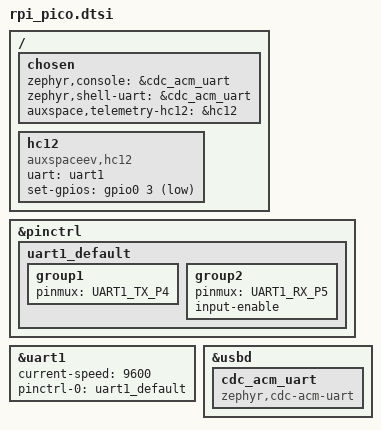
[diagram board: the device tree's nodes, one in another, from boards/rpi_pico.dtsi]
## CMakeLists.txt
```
#-------------------------------------------------------------------------------
# Flight Computer prototype
#
# Copyright (c) 2025-2026 Auxspace e.V.
# SPDX-License-Identifier: Apache-2.0

cmake_minimum_required(VERSION 3.20.0)

# TODO: Exclude zephyr from SCA since it produces false positives
# set(ZEPHYR_SCA_VARIANT gcc)

# Make application-local snippets (e.g. ./snippets/sim) discoverable by
# `west build -S <name>` and twister's SNIPPET= extra_args.
list(APPEND SNIPPET_ROOT ${CMAKE_CURRENT_SOURCE_DIR})

find_package(Zephyr REQUIRED HINTS $ENV{ZEPHYR_BASE})

# For some reason, when using west twister, the app target is not created
# automatically, so we need to create it manually here.
# Building locally and without the zephyr github action, naming this
# "flight_computer" works fine, but as soon as we use west twister inside a
# github-runner context, the target must be named "app":
# > Cannot specify sources for target "app" which is not built by this project.
project(app LANGUAGES C)

target_sources(app PRIVATE
	src/main.c
	src/data.c
	)

target_sources_ifdef(CONFIG_AURORA_FAKE_SENSORS_SYNTH app PRIVATE
	src/fake_sensors.c
	)

if(CONFIG_AURORA_FAKE_SENSORS_REPLAY)
	# Strip surrounding quotes Kconfig keeps on string symbols.
	string(REGEX REPLACE "^\"(.*)\"$" "\\1"
		REPLAY_INPUT_REL "${CONFIG_AURORA_FAKE_SENSORS_REPLAY_INPUT}")
	set(REPLAY_INPUT "${CMAKE_CURRENT_SOURCE_DIR}/../${REPLAY_INPUT_REL}")
	set(REPLAY_GEN  "${CMAKE_CURRENT_SOURCE_DIR}/../tools/gen_flight_replay.py")
	set(REPLAY_OUT  "${CMAKE_CURRENT_BINARY_DIR}/replay_data.c")

	if(NOT EXISTS "${REPLAY_INPUT}")
		message(FATAL_ERROR
			"AURORA_FAKE_SENSORS_REPLAY: input CSV not found: "
			"${REPLAY_INPUT}")
	endif()

	# If a state_audit sits next to flights.csv (default data_logger
	# layout), pass it through so the generator trims to the
	# [BOOST - 4 s, LANDED + 4 s] window.
	get_filename_component(REPLAY_INPUT_DIR "${REPLAY_INPUT}" DIRECTORY)
	set(REPLAY_AUDIT "${REPLAY_INPUT_DIR}/state_audit")
	set(REPLAY_AUDIT_ARGS)
	set(REPLAY_AUDIT_DEPS)
	if(EXISTS "${REPLAY_AUDIT}")
		list(APPEND REPLAY_AUDIT_ARGS --state-audit "${REPLAY_AUDIT}")
		list(APPEND REPLAY_AUDIT_DEPS "${REPLAY_AUDIT}")
    message("-- Found replay audit in flight dir: ${REPLAY_AUDIT}")
	endif()

	add_custom_command(
		OUTPUT  "${REPLAY_OUT}"
		COMMAND ${PYTHON_EXECUTABLE} "${REPLAY_GEN}"
			--input "${REPLAY_INPUT}"
			--output "${REPLAY_OUT}"
			${REPLAY_AUDIT_ARGS}
		DEPENDS "${REPLAY_INPUT}" "${REPLAY_GEN}" ${REPLAY_AUDIT_DEPS}
		COMMENT "Generating replay_data.c from ${REPLAY_INPUT_REL}"
		VERBATIM
	)

	target_sources(app PRIVATE
		src/fake_sensors_replay.c
		"${REPLAY_OUT}"
	)
	target_include_directories(app PRIVATE src)
endif()
```

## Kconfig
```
# Copyright (c) 2025-2026 Auxspace e.V.
# SPDX-License-Identifier: Apache-2.0
#
# This file is the application Kconfig entry point. All application Kconfig
# options can be defined here or included via other application Kconfig files.
# You can browse these options using the west targets menuconfig (terminal) or
# guiconfig (GUI).

menu "Zephyr"

source "Kconfig.zephyr"

endmenu

module = FLIGHT_COMPUTER
module-str = FLIGHT_COMPUTER
source "subsys/logging/Kconfig.template.log_config"

config AURORA_FAKE_SENSORS
	bool "Synthetic IMU/baro data source (no hardware)"
	depends on AURORA_SENSORS
	help
	  Replaces the hardware IMU and barometer polling threads with a
	  synthetic flight-profile generator. The generator publishes
	  imu_data/baro_data messages on the same zbus channels, at the
	  same cadence and thread priorities, so the downstream data path,
	  Kalman filter and state machine can be exercised without real
	  sensors. Works on native_sim and on real hardware targets — use
	  the `sim` snippet (`west build -S sim ...`) to layer this on top
	  of any board. A shell command "sim launch" kicks off the canned
	  ascent/descent profile.

config AURORA_FAKE_SENSORS_REPLAY
	bool "Replay recorded flight log instead of the algorithmic profile"
	depends on IMU && BARO
	select AURORA_FAKE_SENSORS
	help
	  Swap the analytic flight-profile generator (fake_sensors.c) for
	  a playback engine (fake_sensors_replay.c) that streams samples
	  embedded at build time from a recorded flights.csv. Pre-launch
	  the threads hold the rocket stationary by republishing the first
	  recorded sample, so attitude calibration converges as usual; the
	  `sim launch` shell command (or the AURORA_SIM_AUTOTEST autolaunch
	  task) then starts replaying the recording at its original
	  cadence. Implies AURORA_FAKE_SENSORS.

config AURORA_FAKE_SENSORS_SYNTH
	def_bool AURORA_FAKE_SENSORS && !AURORA_FAKE_SENSORS_REPLAY
	help
	  Internal switch: true when AURORA_FAKE_SENSORS is enabled but
	  the replay backend is not, i.e. the algorithmic profile in
	  fake_sensors.c should be compiled in.

config AURORA_FAKE_SENSORS_REPLAY_INPUT
	string "Path to flights.csv used by the replay backend"
	depends on AURORA_FAKE_SENSORS_REPLAY
	default "flight_logs/multimeter/2026-05-03/flight1/flights.csv"
	help
	  Path (relative to the aurora module root, i.e. the directory that
	  contains zephyr/module.yml) to the flights.csv file embedded by
	  the replay generator. May be overridden in prj.conf or via
	  -DCONFIG_AURORA_FAKE_SENSORS_REPLAY_INPUT=... to swap recordings.

config AURORA_SIM_AUTOTEST
	bool "Automated simulation test (CI mode)"
	depends on IMU && BARO
	select AURORA_FAKE_SENSORS
	select ASSERT
	help
	  Enables the full automated flight simulation for CI. Pulls in fake
	  sensors and assertion support, then starts a thread that waits for
	  altitude calibration, and auto-launches the flight
	  profile. Exits with code 0 on SM_LANDED, code 1 on SM_ERROR or after
	  AURORA_SIM_AUTOLAUNCH_TIMEOUT_MS. Run ./zephyr.exe and check the process exit code.

config AURORA_SIM_AUTOLAUNCH_TIMEOUT_MS
	int "Autolaunch watchdog timeout (ms)"
	depends on AURORA_SIM_AUTOTEST
	default 120000
	help
	  Maximum time in milliseconds the autolaunch thread waits for SM_LANDED
	  after triggering the flight profile. Exits with code 1 if this
	  deadline is exceeded.
```

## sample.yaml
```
# Copyright (c) 2026 Auxspace e.V.
# SPDX-License-Identifier: Apache-2.0
#
# This file is provided so that the application can be compiled using Twister,
# the Zephyr testing tool. In this file, multiple combinations can be specified,
# so that you can easily test all of them locally or in CI.
sample:
  description: Flight Computer Application
  name: Flight Computer
common:
  build_only: true
  modules:
    - fatfs
tests:
  app.default:
    platform_allow:
      - sensor_board_v2/rp2350a/hazard3
    integration_platforms:
      - sensor_board_v2/rp2350a/hazard3
  app.native_sim.replay:
    build_only: false
    timeout: 180
    harness: console
    harness_config:
      type: one_line
      regex:
        - "simulation complete"
    extra_overlay_confs:
      - boards/native_sim.conf
    extra_dtc_overlay_files:
      - boards/native_sim.overlay
    extra_configs:
      - CONFIG_AURORA_SIM_AUTOTEST=y
      - CONFIG_AURORA_FAKE_SENSORS_REPLAY=y
    platform_allow:
      - native_sim/native/64
    integration_platforms:
      - native_sim/native/64
  app.default.sysbuild:
    sysbuild: true
    platform_allow:
      - sensor_board_v2/rp2040
      - micrometer@1/esp32s3/procpu
      - micrometer@2/esp32s3/procpu
    integration_platforms:
      - sensor_board_v2/rp2040
      - micrometer@1/esp32s3/procpu
      - micrometer@2/esp32s3/procpu
  app.bench:
    extra_args: SNIPPET="sim;nodisk"
    platform_allow:
      - rpi_pico/rp2040/w
      - rpi_pico2/rp2350a/m33/w
      - sensor_board_v2/rp2040
      - sensor_board_v2/rp2350a/hazard3
    integration_platforms:
      - rpi_pico/rp2040/w
      - rpi_pico2/rp2350a/m33/w
      - sensor_board_v2/rp2040
      - sensor_board_v2/rp2350a/hazard3
  app.debug:
    extra_overlay_confs:
      - debug.conf
    platform_allow:
      - sensor_board_v2/rp2350a/hazard3
    integration_platforms:
      - sensor_board_v2/rp2350a/hazard3
  app.debug.sysbuild:
    sysbuild: true
    extra_overlay_confs:
      - debug.conf
    platform_allow:
      - sensor_board_v2/rp2040
      - micrometer@1/esp32s3/procpu
      - micrometer@2/esp32s3/procpu
    integration_platforms:
      - sensor_board_v2/rp2040
      - micrometer@1/esp32s3/procpu
      - micrometer@2/esp32s3/procpu
```

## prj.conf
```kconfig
# Copyright (c) 2026 Auxspace e.V.
# SPDX-License-Identifier: Apache-2.0
#
# common options, which apply to all boards (will be duplicated in board configs)

# Console and Shell
CONFIG_SHELL=y
CONFIG_SENSOR_SHELL=y

# Boot banner
CONFIG_BOOT_BANNER_STRING="Booting AURORA"

# Logging
CONFIG_LOG=y
CONFIG_LOG_FLUSH_SLEEP_US=1000
CONFIG_LOG_DEFAULT_LEVEL=3
CONFIG_LOG_TIMESTAMP_USE_REALTIME=y
CONFIG_LOG_SPEED=y
CONFIG_LOG_THREAD_ID_PREFIX=y
CONFIG_LOG_INFO_COLOR_GREEN=y
CONFIG_LOG_DBG_COLOR_BLUE=y
CONFIG_LOG_OUTPUT_FORMAT_TIME_TIMESTAMP=y
# CONFIG_LOG_BACKEND_FS_APPEND_TO_NEWEST_FILE is not set
# CONFIG_LOG_MEM_UTILIZATION is not set
CONFIG_LOG_CMDS=y
CONFIG_LOG_RATELIMIT_INTERVAL_MS=500

# State machine
CONFIG_AURORA_STATE_MACHINE=y
CONFIG_AURORA_STATE_MACHINE_SHELL=y

CONFIG_ZBUS=y
CONFIG_ZBUS_CHANNEL_NAME=y
CONFIG_ZBUS_MSG_SUBSCRIBER=y
# Headroom so a transient SD write stall doesn't exhaust the pool and drop
# sensor publishes.
CONFIG_ZBUS_MSG_SUBSCRIBER_NET_BUF_POOL_SIZE=64

# Runtime healthchecks and supervision
CONFIG_STACK_SENTINEL=y
CONFIG_ASSERT=y
```

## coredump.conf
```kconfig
# Copyright (c) 2026 Auxspace e.V.
# SPDX-License-Identifier: Apache-2.0
#
# Post-mortem core dump persisted to the on-board "coredump" flash
# partition, then read back over the shell after the board comes up again:
#
#   uart:~$ coredump find     # is a dump stored, and is it valid?
#   uart:~$ coredump print    # emit the "#CD:" hex stream
#   uart:~$ coredump erase    # invalidate it before the next run
#
# Decode off-target against the matching ELF:
#   zephyr/scripts/coredump/coredump_serial_log_parse.py <captured> out.bin
#   zephyr/scripts/coredump/coredump_gdbserver.py build/zephyr/zephyr.elf out.bin
#
# Stack with the debug overlay for symbols + a text backtrace:
#   west build -b micrometer/esp32s3/procpu@2 aurora/flight_computer \
#       -- -DEXTRA_CONF_FILE="debug.conf;coredump.conf"
#
# Why flash and not BACKEND_LOGGING: on micrometer@2 the console is the
# ESP32-S3 USB-Serial-JTAG, whose poll_out (serial_esp32_usb.c) silently
# DISCARDS characters once the 64-byte TX FIFO stays full for 50 ms. A
# coredump is the largest burst the firmware ever emits and it is written
# in panic mode, so streaming it over that console loses most of it with no
# "dropped" marker. Flash survives the fault, the reboot, and a power
# cycle; the shell read-back afterwards is interrupt-driven and properly
# back-pressured, so it does not drop.

CONFIG_DEBUG_COREDUMP=y
CONFIG_DEBUG_COREDUMP_BACKEND_FLASH_PARTITION=y

# Read the stored dump back out on the next boot.
CONFIG_DEBUG_COREDUMP_SHELL=y

# Registers + the faulting thread's stack only: enough to reconstruct the
# backtrace of a NULL-deref crash. Switch to
# CONFIG_DEBUG_COREDUMP_MEMORY_DUMP_THREADS=y if you need every thread's
# stack -- but see the size budget below first, it will not fit.
CONFIG_DEBUG_COREDUMP_MEMORY_DUMP_MIN=y

# Size budget. The coredump partition inherited from
# espressif/partitions_0x0_amp_4M.dtsi is 4 KiB at 0x3ff000; the backend's
# 16-byte header (write-block-size is 4, so no erase-block padding) leaves
# 4080 bytes for data. The stack-top limits default to -1 == "dump to the
# end of the stack region", which for a 4 KiB thread stack overruns the
# partition and truncates the dump. Bound them so the whole thing fits:
#
#   coredump hdr ~12 + Xtensa arch block ~200 + k_thread ~350
#   + block headers ~30 + 2048 stack  ==  ~2.6 KiB of 4080.
#
# 2 KiB of stack top is generous on Xtensa, where register-window spills
# make frames large.
CONFIG_DEBUG_COREDUMP_THREAD_STACK_TOP=y
CONFIG_DEBUG_COREDUMP_THREAD_STACK_TOP_LIMIT_FOR_CURRENT=2048
CONFIG_DEBUG_COREDUMP_THREAD_STACK_TOP_LIMIT=1024

# Take the SD card off the panic path. The FS log backend flushes
# synchronously during a panic; a real crash then looks like a freeze.
# Console/UART still gets everything. Disabling it here also doubles as the
# test for whether the SD/FATFS is itself the freeze source.
# if the freezes stop with this off, the card/filesystem is the culprit.
CONFIG_LOG_BACKEND_FS=n
```

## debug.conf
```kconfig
# Copyright (c) 2021 Nordic Semiconductor ASA
# Copyright (c) 2026 Auxspace e.V.
# SPDX-License-Identifier: Apache-2.0
#
# This is a Kconfig fragment which can be used to enable debug-related options
# in the application. See the README for more details.

# kernel
CONFIG_DEBUG=y
CONFIG_DEBUG_THREAD_INFO=y

# Fatal-error handling.
#
# Zephyr's default with RESET_ON_FATAL_ERROR=n is arch_system_halt(): the
# board stops dead where it faulted. On micrometer@2 that is
# indistinguishable from a brownout or a flat pack, because the halt takes
# the console with it and the panic banner is lost in the USB-Serial-JTAG
# FIFO (see coredump.conf). Rebooting instead means the board comes back,
# re-prints the boot banner -- which is itself the proof that this was a
# fault and not a power loss -- and can be asked for the stored coredump.
#
# Debug-only on purpose: a flight build should not silently reboot a live
# state machine, so this stays out of prj.conf.
CONFIG_RESET_ON_FATAL_ERROR=y

# Reset-cause reporting. hwinfo_esp32 distinguishes POR / PIN / SOFTWARE /
# WATCHDOG / CPU_LOCKUP / BROWNOUT / LOW_POWER_WAKE, which is the one thing
# the console genuinely cannot tell you: whether the board panicked, was
# reset by the watchdog, browned out, or just lost power. main() logs and
# clears it at boot.
CONFIG_HWINFO=y

# Stack-overflow sanitisers
CONFIG_HW_STACK_PROTECTION=y
CONFIG_INIT_STACKS=y
CONFIG_THREAD_STACK_INFO=y
CONFIG_STACK_USAGE=y
CONFIG_EXCEPTION_STACK_TRACE=y

# compiler
CONFIG_SYMTAB=y
CONFIG_SYMTAB_SHELL=y
CONFIG_DEBUG_OPTIMIZATIONS=y
# Keep file:line (that is what names a panic) but drop the condition
# expression, which is the long half of every assert string. Assert strings
# land in DRAM rodata on esp32s3, and DRAM is the binding constraint here.
CONFIG_ASSERT_NO_COND_INFO=y

# Paying for CONFIG_ASSERT: its strings cost ~20 KB of DRAM, which does not
# fit on micrometer@2 at the production buffer sizes. Buy it back from the
# post-flight conversion staging buffers -- they only set how often
# data_logger_convert() calls fs_write(), so the cost is more/smaller SD
# writes after landing and nothing at flight time.
#
# These belong here rather than in the board .conf: EXTRA_CONF_FILE is merged
# after the board fragment, so they override it for debug builds only and the
# production image keeps the full 16 KiB buffers.
CONFIG_DATA_LOGGER_CSV_BUF_SIZE=8192

# thread analyzing
CONFIG_THREAD_ANALYZER=y
CONFIG_THREAD_ANALYZER_AUTO=y
CONFIG_THREAD_ANALYZER_AUTO_STACK_SIZE=2048
CONFIG_THREAD_ANALYZER_USE_LOG=y

# logging
CONFIG_LOG=y

CONFIG_FS_LOG_LEVEL_DBG=y
CONFIG_PYRO_LOG_LEVEL_DBG=y
CONFIG_AURORA_SENSORS_LOG_LEVEL_DBG=y
CONFIG_AURORA_FILTER_LOG_LEVEL_DBG=y
CONFIG_DATA_LOGGER_LOG_LEVEL_DBG=y
CONFIG_STATE_MACHINE_LOG_LEVEL_DBG=y
CONFIG_AURORA_NOTIFY_LOG_LEVEL_DBG=y
CONFIG_AURORA_PWM_MELODY_LOG_LEVEL_DBG=y
CONFIG_AURORA_POWERFAIL_LOG_LEVEL_DBG=y
CONFIG_FLIGHT_COMPUTER_LOG_LEVEL_DBG=y
CONFIG_AURORA_TELEMETRY_LOG_LEVEL_DBG=y
CONFIG_AURORA_PAD_LINK_LOG_LEVEL_DBG=y
CONFIG_AURORA_WATCHDOG_LOG_LEVEL_DBG=y

# powerfail
CONFIG_AURORA_POWERFAIL_SHUTDOWN=n

# Extra Shells for Debugging
CONFIG_ADC_SHELL=y
CONFIG_AURORA_STATE_MACHINE_SHELL=y
CONFIG_CAN_SHELL=y
CONFIG_GPIO_SHELL=y
CONFIG_PWM_SHELL=y
CONFIG_PYRO_SHELL=y
CONFIG_WDT_SHELL=y
```

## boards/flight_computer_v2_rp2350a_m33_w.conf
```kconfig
CONFIG_USE_DT_CODE_PARTITION=y
CONFIG_MAIN_STACK_SIZE=2048
CONFIG_CLOCK_CONTROL=y
CONFIG_BUILD_OUTPUT_HEX=y
CONFIG_GPIO=y
CONFIG_RESET=y
CONFIG_AURORA_SENSORS=y
CONFIG_IMU=y
CONFIG_IMU_FREQUENCY=100
CONFIG_BARO=y
CONFIG_BARO_FREQUENCY=100
CONFIG_FILTER=y
CONFIG_UART_CONSOLE=y
CONFIG_SENSOR=y
CONFIG_LSM6DSO_ENABLE_TEMP=y
CONFIG_UART_LINE_CTRL=y
CONFIG_FILE_SYSTEM=y
CONFIG_FILE_SYSTEM_SHELL=y
CONFIG_FILE_SYSTEM_SHELL_TEST_COMMANDS=y
CONFIG_FILE_SYSTEM_MKFS=y
CONFIG_FAT_FILESYSTEM_ELM=y
CONFIG_FS_FATFS_LFN=y
CONFIG_FS_FATFS_LFN_MODE_HEAP=y
CONFIG_FS_FATFS_REENTRANT=y
CONFIG_FS_FATFS_CUSTOM_MOUNT_POINT_COUNT=1
CONFIG_FS_FATFS_CUSTOM_MOUNT_POINTS="MMC"
CONFIG_LOG_BACKEND_FS=y
CONFIG_LOG_BACKEND_FS_AUTOSTART=n
CONFIG_LOG_BACKEND_FS_DIR="/MMC:/LOGS"
CONFIG_LOG_BACKEND_FS_FILES_LIMIT=512
CONFIG_LOG_BACKEND_FS_FILE_SIZE=100000000
CONFIG_LOG_BACKEND_UART=y
CONFIG_LOG_BACKEND_UART_BUFFER_SIZE=32
CONFIG_CBPRINTF_FP_SUPPORT=y
CONFIG_DATA_LOGGER=y
CONFIG_DATA_LOGGER_BIN_BACKEND_DISK=y
CONFIG_DATA_LOGGER_DISK_AUTO_MKFS=y
CONFIG_DATA_LOGGER_CONVERT_INFLUX=n
CONFIG_DATA_LOGGER_CONVERT_CSV=y
CONFIG_DATA_LOGGER_BASE_PATH="/MMC:/DATA"
CONFIG_DATA_LOGGER_SHELL=y
CONFIG_MMC_STACK=y
CONFIG_AURORA_STATE_MACHINE_AUDIT=y
CONFIG_AURORA_STATE_MACHINE_AUDIT_BASE_PATH="/MMC:/STATE"
CONFIG_USB_DEVICE_STACK_NEXT=y
CONFIG_USBD_CDC_ACM_LOG_LEVEL_OFF=y
CONFIG_CDC_ACM_SERIAL_INITIALIZE_AT_BOOT=y
CONFIG_BUILD_OUTPUT_UF2=y
```

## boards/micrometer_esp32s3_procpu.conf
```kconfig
CONFIG_USE_DT_CODE_PARTITION=y
CONFIG_GPIO=y
CONFIG_PYRO=y
CONFIG_AURORA_SENSORS=y
CONFIG_IMU=y
CONFIG_IMU_UP_AXIS_POS_Y=y
CONFIG_BARO=y
CONFIG_FILTER=y
CONFIG_FILTER_Q_VEL_MILLISCALE=3000
CONFIG_FILTER_R_MILLISCALE=6000
CONFIG_FILTER_APOGEE_DEBOUNCE_SAMPLES=3
CONFIG_ADC=y
CONFIG_CAN=y
CONFIG_UART_CONSOLE=y
CONFIG_PWM=y
CONFIG_LED=y
CONFIG_LED_PWM=y
CONFIG_SENSOR=y
CONFIG_LSM6DSO=y
# Barometer differs per board revision; its driver Kconfig lives in the
# revision-specific configs (micrometer_esp32s3_procpu_{1,2}.conf).
CONFIG_UART_LINE_CTRL=y
# CONFIG_UDC_DRIVER is not set
# CONFIG_UDC_DWC2 is not set
# CONFIG_USB_DEVICE_STACK is not set
# CONFIG_USB_DEVICE_STACK_NEXT is not set
# CONFIG_COMMON_LIBC_REMOVE is not set
CONFIG_FILE_SYSTEM=y
CONFIG_FILE_SYSTEM_SHELL=y
CONFIG_FILE_SYSTEM_SHELL_TEST_COMMANDS=y
CONFIG_FILE_SYSTEM_MKFS=y
CONFIG_FAT_FILESYSTEM_ELM=y
CONFIG_FS_FATFS_LFN=y
CONFIG_FS_FATFS_LFN_MODE_HEAP=y
CONFIG_FS_FATFS_REENTRANT=y
CONFIG_FS_FATFS_CUSTOM_MOUNT_POINT_COUNT=1
CONFIG_FS_FATFS_CUSTOM_MOUNT_POINTS="MMC"
CONFIG_LOG_BUFFER_SIZE=8192
CONFIG_LOG_BACKEND_FS=y
CONFIG_LOG_BACKEND_FS_DIR="/MMC:/LOGS"
CONFIG_LOG_BACKEND_FS_FILE_PREFIX="LOG."
CONFIG_LOG_BACKEND_FS_FILES_LIMIT=512
CONFIG_LOG_BACKEND_FS_FILE_SIZE=100000000
CONFIG_LOG_BACKEND_FS_AUTOSTART=n
CONFIG_LOG_BACKEND_UART=y
CONFIG_LOG_BACKEND_UART_BUFFER_SIZE=32
CONFIG_SHELL_LOG_BACKEND=n
CONFIG_DATA_LOGGER=y
CONFIG_DATA_LOGGER_BIN_BACKEND_DISK=y
CONFIG_DATA_LOGGER_DISK_AUTO_MKFS=y
CONFIG_DATA_LOGGER_CONVERT_INFLUX=n
CONFIG_DATA_LOGGER_CONVERT_CSV=y
CONFIG_DATA_LOGGER_BASE_PATH="/MMC:/DATA"
CONFIG_DATA_LOGGER_SHELL=y
CONFIG_MMC_STACK=y
CONFIG_AURORA_NOTIFY=y
CONFIG_AURORA_NOTIFY_BUZZER=y
CONFIG_AURORA_NOTIFY_LED=y
CONFIG_AURORA_WATCHDOG=y
CONFIG_AURORA_STATE_MACHINE_AUDIT=y
CONFIG_AURORA_STATE_MACHINE_AUDIT_BASE_PATH="/MMC:/STATE"
CONFIG_AURORA_STATE_MACHINE_RBF=y
CONFIG_AURORA_STATE_MACHINE_RETAIN=y

CONFIG_AURORA_PAD_LINK=y
CONFIG_BT_L2CAP_TX_MTU=247
CONFIG_BT_BUF_ACL_RX_SIZE=251
CONFIG_BT_BUF_ACL_TX_SIZE=251
CONFIG_COMMON_LIBC_MALLOC_ARENA_SIZE=16384
CONFIG_HEAP_MEM_POOL_SIZE=32768

# Post-flight conversion staging. Larger buffers mean fewer fs_write calls
# while the converter is also reading the raw flight-log region off the same
# card. debug.conf halves these to make room for CONFIG_ASSERT.
CONFIG_DATA_LOGGER_CSV_BUF_SIZE=16384

# Flight of about 50-60 m height with a 6N Motor

# Metrics
CONFIG_BOOST_ACCELERATION=15
CONFIG_BOOST_ALTITUDE=5
CONFIG_BURNOUT_ACCELERATION=10
CONFIG_MAIN_DESCENT_HEIGHT=25
CONFIG_LANDING_VELOCITY=2

# Timers
CONFIG_BOOST_TIMER_MS=200

# Timeouts
CONFIG_APOGEE_TIMEOUT_MS=20000
CONFIG_MAIN_TIMEOUT_MS=2000

# I2C
CONFIG_I2C=y
CONFIG_I2C_BUS_RECOVERY=y

# Flight thresholds persist in the sm-config flash page (see micrometer_v2.dtsi).
CONFIG_FLASH=y
CONFIG_AURORA_STATE_MACHINE_CONFIG_STORE=y

# Every bmp581 register access goes through the RTIO work queue, so the baro
# poller alone keeps items in flight continuously.
CONFIG_RTIO_WORKQ_POOL_ITEMS=16

# Stacks
CONFIG_IDLE_STACK_SIZE=2048
CONFIG_ISR_STACK_SIZE=4096
CONFIG_BT_TX_PROCESSOR_STACK_SIZE=2048
CONFIG_RTIO_WORKQ_THREADS_POOL_STACK_SIZE=2048
CONFIG_LOG_PROCESS_THREAD_STACK_SIZE=4096
CONFIG_SHELL_STACK_SIZE=4096
CONFIG_SYSTEM_WORKQUEUE_STACK_SIZE=4096
CONFIG_LSM6DSO_THREAD_STACK_SIZE=4096
CONFIG_DATA_LOGGER_BIN_WRITER_STACK_SIZE=4096
CONFIG_DATA_LOGGER_LOGGER_STACK_SIZE=4096
CONFIG_DATA_LOGGER_CONVERTER_STACK_SIZE=4096
```

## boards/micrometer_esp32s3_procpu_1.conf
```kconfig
# Copyright (c) 2026 Auxspace e.V.
# SPDX-License-Identifier: Apache-2.0

CONFIG_LPS22HH=y
CONFIG_LPS22HH_TRIGGER_OWN_THREAD=y
CONFIG_LPS22HH_THREAD_STACK_SIZE=1024
CONFIG_LPS22HH_THREAD_PRIORITY=4
```

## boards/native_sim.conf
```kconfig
# native_sim target for data-path / filter / thread-priority testing.
# Real sensor drivers are replaced by the synthetic profile generator.

CONFIG_MAIN_STACK_SIZE=4096

# Console over stdout
CONFIG_UART_CONSOLE=y
CONFIG_UART_NATIVE_PTY_0_ON_STDINOUT=y
CONFIG_SHELL_STACK_SIZE=4096

# FAT filesystem on a RAM disk
CONFIG_DISK_DRIVERS=y
CONFIG_FILE_SYSTEM=y
CONFIG_FILE_SYSTEM_SHELL=y
CONFIG_FILE_SYSTEM_SHELL_TEST_COMMANDS=y
CONFIG_FILE_SYSTEM_MKFS=y
CONFIG_FAT_FILESYSTEM_ELM=y
CONFIG_FS_FATFS_LFN=y
CONFIG_FS_FATFS_FSTAB_AUTOMOUNT=y
# logging
CONFIG_LOG_MODE_DEFERRED=y
CONFIG_LOG_BACKEND_UART=n
CONFIG_SHELL_LOG_BACKEND=n
CONFIG_LOG_BACKEND_FS=y
CONFIG_LOG_BACKEND_FS_DIR="/RAM:/logs"
CONFIG_LOG_BACKEND_FS_FILES_LIMIT=512
CONFIG_LOG_PROCESS_THREAD_STACK_SIZE=4096
# Data logger
CONFIG_DATA_LOGGER=y
CONFIG_DATA_LOGGER_BIN_BACKEND_DISK=y
CONFIG_DATA_LOGGER_DISK_AUTO_MKFS=y
CONFIG_DATA_LOGGER_CONVERT_INFLUX=n
CONFIG_DATA_LOGGER_CONVERT_CSV=y
CONFIG_DATA_LOGGER_BASE_PATH="/RAM:/data"
CONFIG_DATA_LOGGER_SHELL=y
CONFIG_DATA_LOGGER_LOG_LEVEL_DBG=y
# State machine audit
CONFIG_AURORA_STATE_MACHINE_AUDIT=y
CONFIG_AURORA_STATE_MACHINE_AUDIT_BASE_PATH="/RAM:/state"
# Filtering
CONFIG_FILTER=y
CONFIG_FILTER_Q_VEL_MILLISCALE=3000
CONFIG_FILTER_R_MILLISCALE=6000
CONFIG_FILTER_APOGEE_DEBOUNCE_SAMPLES=3

# Heap required by k_malloc in formatter backends
CONFIG_HEAP_MEM_POOL_SIZE=8192

# Sanitizer
CONFIG_ASAN=y
CONFIG_UBSAN=y
CONFIG_UBSAN_LIBRARY=y

# Aurora sensor HAL stays on so zbus channels and conversion helpers are built,
# but AURORA_FAKE_SENSORS replaces the hardware polling threads.
CONFIG_SENSOR=y
CONFIG_AURORA_SENSORS=y
CONFIG_IMU=y
CONFIG_IMU_UP_AXIS_POS_Y=y
CONFIG_IMU_FREQUENCY=1000
CONFIG_IMU_CALIBRATION_SAMPLES=100
CONFIG_BARO=y
CONFIG_BARO_FREQUENCY=1000
CONFIG_FILTER=y
CONFIG_FILTER_Q_VEL_MILLISCALE=3000
CONFIG_FILTER_R_MILLISCALE=6000
CONFIG_FILTER_APOGEE_DEBOUNCE_SAMPLES=3
CONFIG_AURORA_FAKE_SENSORS=y

# No pyro, no storage, no notifications, no powerfail on native_sim.

# Thresholds mirror the simulated short-flight profile.
CONFIG_BOOST_ACCELERATION=15
CONFIG_BOOST_ALTITUDE=5
CONFIG_BURNOUT_ACCELERATION=10
CONFIG_MAIN_DESCENT_HEIGHT=50
CONFIG_LANDING_VELOCITY=2
CONFIG_BOOST_TIMER_MS=200
CONFIG_APOGEE_TIMEOUT_MS=60000
CONFIG_MAIN_TIMEOUT_MS=2000
```

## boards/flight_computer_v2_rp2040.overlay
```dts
/*
 * Copyright (c) 2026 Auxspace e.V.
 * SPDX-License-Identifier: Apache-2.0
 *
 * RP2040 flight computer overlay.  The flight log lives on a sector range
 * of the SD card (DATA_LOGGER_BIN_BACKEND_DISK), so internal flash is
 * reserved entirely for code; no flight_log partition is carved out.
 *
 * The flight-log region starts 1 GiB into the card and reserves
 * 256 MiB.  The FATFS volume mounted at /MMC: must be sized to the
 * first 1 GiB of the card (i.e. created with mkfs limited to that
 * range) so it does not overlap the raw region.
 */

#include "flight_computer_v2.dtsi"

&timer {
	status = "okay";
};

/ {
	chosen {
		auxspace,flight-log-disk = &flight_log_disk;
	};

	flight_log_disk: flight-log-disk {
		compatible = "auxspaceev,flight-log-disk";
		disk-name = "MMC";
		offset-bytes = <0x2 0x00000000>;	/* 8 GiB */
		size-bytes   = <0x1 0xF0000000>;	/* 7 GiB and 512 MiB */
	};
};
```

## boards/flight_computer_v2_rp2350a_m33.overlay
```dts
/*
 * Copyright (c) 2026 Auxspace e.V.
 * SPDX-License-Identifier: Apache-2.0
 *
 * RP2350a flight computer overlay.  The flight log lives on a sector
 * range of the SD card (DATA_LOGGER_BIN_BACKEND_DISK), so internal
 * flash is reserved entirely for code.
 *
 * The flight-log region starts 1 GiB into the card and reserves
 * 256 MiB.  The FATFS volume mounted at /MMC: must be sized to the
 * first 1 GiB of the card so it does not overlap the raw region.
 */

#include "flight_computer_v2.dtsi"

&timer0 {
	status = "okay";
};

/ {
	chosen {
		auxspace,flight-log-disk = &flight_log_disk;
	};

	flight_log_disk: flight-log-disk {
		compatible = "auxspaceev,flight-log-disk";
		disk-name = "MMC";
		offset-bytes = <0x2 0x00000000>;	/* 8 GiB */
		size-bytes   = <0x1 0xF0000000>;	/* 7 GiB and 512 MiB */
	};
};
```

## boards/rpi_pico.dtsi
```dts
/*
 * Copyright (c) 2026 Auxspace e.V.
 * SPDX-License-Identifier: Apache-2.0
 *
 * Pico bench overlay: wires an HC-12 to uart1.
 *   TX  -> GP4
 *   RX  -> GP5
 *   SET -> GP3  (active-low; lets the telemetry shell flip the module
 *                into AT mode)
 *
 * Console/shell live on USB CDC.
 */

/ {
	chosen {
		zephyr,console = &cdc_acm_uart;
		zephyr,shell-uart = &cdc_acm_uart;
		auxspace,telemetry-hc12 = &hc12;
	};

	hc12: hc12 {
		compatible = "auxspaceev,hc12";
		uart = <&uart1>;
		set-gpios = <&gpio0 3 GPIO_ACTIVE_LOW>;
		status = "okay";
	};
};

&pinctrl {
	uart1_default: uart1_default {
		group1 {
			pinmux = <UART1_TX_P4>;
		};
		group2 {
			pinmux = <UART1_RX_P5>;
			input-enable;
		};
	};
};

&uart1 {
	current-speed = <9600>;
	pinctrl-0 = <&uart1_default>;
	pinctrl-names = "default";
	status = "okay";
};

zephyr_udc0: &usbd {
	cdc_acm_uart: cdc_acm_uart {
		compatible = "zephyr,cdc-acm-uart";
	};
};
```

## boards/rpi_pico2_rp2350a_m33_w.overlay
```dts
/*
 * Copyright (c) 2026 Auxspace e.V.
 * SPDX-License-Identifier: Apache-2.0
 *
 * Pico 2 W bench overlay
 */

#include <zephyr/dt-bindings/pinctrl/rpi-pico-rp2350a-pinctrl.h>
#include "rpi_pico.dtsi"
```

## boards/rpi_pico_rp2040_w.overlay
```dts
/*
 * Copyright (c) 2026 Auxspace e.V.
 * SPDX-License-Identifier: Apache-2.0
 *
 * Pico W bench overlay.
 */

#include <zephyr/dt-bindings/pinctrl/rpi-pico-rp2040-pinctrl.h>
#include "rpi_pico.dtsi"
```

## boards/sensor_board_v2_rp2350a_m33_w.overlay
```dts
/*
 * Copyright (c) 2026 Auxspace e.V.
 * SPDX-License-Identifier: Apache-2.0
 *
 * RP2350a sensor board overlay.  The flight log lives on a sector
 * range of the SD card (DATA_LOGGER_BIN_BACKEND_DISK), so internal
 * flash is reserved entirely for code.
 *
 * The flight-log region starts 1 GiB into the card and reserves
 * 256 MiB.  The FATFS volume mounted at /MMC: must be sized to the
 * first 1 GiB of the card so it does not overlap the raw region.
 */

#include "sensor_board_v2.dtsi"

&timer0 {
	status = "okay";
};

/ {
	chosen {
		auxspace,flight-log-disk = &flight_log_disk;
	};

	flight_log_disk: flight-log-disk {
		compatible = "auxspaceev,flight-log-disk";
		disk-name = "MMC";
		offset-bytes = <0x2 0x00000000>;	/* 8 GiB */
		size-bytes   = <0x1 0xF0000000>;	/* 7 GiB and 512 MiB */
	};
};
```

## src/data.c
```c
/**
 * @file data.c
 * @brief Flight-time logging lifecycle and telemetry glue for the flight computer.
 *
 * Drives the binary data logger across flight state transitions and enqueues
 * state-machine telemetry datapoints.
 *
 * Copyright (c) 2025-2026 Auxspace e.V.
 * SPDX-License-Identifier: Apache-2.0
 */

#include "data.h"
#include <stdint.h>
#include <stdio.h>
#include <zephyr/device.h>
#include <zephyr/drivers/sensor.h>
#include <zephyr/fs/fs.h>
#include <zephyr/logging/log.h>
#include <aurora/lib/baro.h>
#include <aurora/lib/data_logger.h>
#include <aurora/lib/notify.h>
#include <aurora/lib/state/state.h>

#if defined(CONFIG_AURORA_PAD_LINK)
#include <aurora/lib/pad_link.h>
#endif /* CONFIG_AURORA_PAD_LINK */

#if defined(CONFIG_DATA_LOGGER_BIN)
LOG_MODULE_DECLARE(main, CONFIG_FLIGHT_COMPUTER_LOG_LEVEL);

K_THREAD_DEFINE(logger_thread, CONFIG_DATA_LOGGER_LOGGER_STACK_SIZE, logger_task, NULL, NULL, NULL,
		8, 0, 0);
K_THREAD_DEFINE(converter_thread, CONFIG_DATA_LOGGER_CONVERTER_STACK_SIZE, converter_task, NULL,
		NULL, NULL, 9, 0, 0);

/* Latched (until reboot) when opening the flight log at ARM time fails.
 * Feeds log_flight_log_online() so the state machine drops back from ARMED
 * to IDLE instead of sitting armed without a recording.  Deliberately never
 * cleared: clearing it on disarm would let the unchanged inputs re-arm
 * immediately and oscillate the pyro channels.
 */
static atomic_t flight_recording_failed = ATOMIC_INIT(0);

static void log_begin_flight(void)
{
	if (k_sem_take(&convert_idle, K_MSEC(LOG_ARM_CONVERT_TIMEOUT_MS)) != 0) {
		LOG_ERR("ARMED: prior conversion still running after %d ms — "
				"flight will not be logged",
			LOG_ARM_CONVERT_TIMEOUT_MS);
		atomic_set(&flight_recording_failed, 1);
#if defined(CONFIG_AURORA_NOTIFY)
		notify_error();
#endif
		return;
	}
	k_sem_give(&convert_idle);

	/* Deliberately no memset of sm_logger here since its state carries the
	 * mutex that serialises logger_task against data_logger_close().
	 */
	if (data_logger_init(&sm_logger, "flight", &data_logger_bin_formatter) != 0) {
		LOG_ERR("data_logger_init failed");
		atomic_set(&flight_recording_failed, 1);
#if defined(CONFIG_AURORA_NOTIFY)
		notify_error();
#endif
		return;
	}
	data_logger_set_default(&sm_logger);
	if (data_logger_start(&sm_logger) != 0) {
		LOG_ERR("data_logger_start failed");
		atomic_set(&flight_recording_failed, 1);
		(void)data_logger_close(&sm_logger);
		data_logger_set_default(NULL);
#if defined(CONFIG_AURORA_NOTIFY)
		notify_error();
#endif
		return;
	}

	atomic_set(&sm_logger_live, 1);
}

static void log_end_flight(void)
{
	if (!atomic_get(&sm_logger_live)) {
		return;
	}
	atomic_set(&sm_logger_live, 0);

	(void)data_logger_stop(&sm_logger);
	(void)data_logger_close(&sm_logger);
	data_logger_set_default(NULL);

	k_sem_give(&convert_request);
}

/* Delayable close: scheduled by the state-machine task on entry to
 * LANDED so the post-landed pad window gets logged before the logger is
 * closed and conversion kicks in.
 */
static void log_end_work_handler(struct k_work *work)
{
	ARG_UNUSED(work);
	log_end_flight();
}
static K_WORK_DELAYABLE_DEFINE(log_end_work, log_end_work_handler);
bool log_flight_log_online(void)
{
	/* An ARM-time open failure outranks the boot latch: the disk looked
	 * fine at boot but the recorder could not be opened when it mattered.
	 */
	if (atomic_get(&flight_recording_failed)) {
		return false;
	}
#if defined(CONFIG_DATA_LOGGER_DISK_AUTO_MKFS)
	return flight_log_online();
#else
	/* No disk bring-up module.  Nothing to gate on at boot. */
	return true;
#endif
}

void log_handle_flight_lifecycle(const enum sm_state prev_state, const enum sm_state state)
{
	/* Flight-time logging lifecycle:
	 *  - IDLE→ARMED:  open a fresh binary log (cancel any
	 *                 still-pending deferred close from a
	 *                 previous flight first). Calibration itself
	 *                 runs continuously while IDLE, potentially
	 *                 well before this arm edge, so it is
	 *                 deliberately not captured -- only the
	 *                 bounded flight-adjacent window from arming
	 *                 onward is.
	 *  - ARMED→BOOST: hand the formatter a BOOST event so
	 *                 the circular ring freezes forward.
	 *  - →LANDED:     hand a LANDED event and schedule the
	 *                 close POST_LANDED_PAD_MS later so the
	 *                 tail of the flight gets captured.
	 *  - →IDLE/ERROR: close immediately (no pad); cancel
	 *                 any pending deferred close.
	 */
	if (prev_state == SM_IDLE && state == SM_ARMED) {
		(void)k_work_cancel_delayable(&log_end_work);
		log_begin_flight();
	} else if (prev_state == SM_ARMED && state == SM_BOOST) {
		(void)data_logger_event(&sm_logger, DLE_BOOST);
	} else if (state == SM_LANDED) {
		(void)data_logger_event(&sm_logger, DLE_LANDED);
		(void)k_work_schedule(&log_end_work, K_MSEC(CONFIG_DATA_LOGGER_BIN_POST_LANDED_PAD_MS));
	} else if (state == SM_IDLE || state == SM_ERROR) {
		(void)k_work_cancel_delayable(&log_end_work);
		log_end_flight();
	}
}

void log_flight_telemetry(void)
{
	struct sm_inputs sm_in;
	sm_get_inputs(&sm_in);

	uint64_t ts = k_ticks_to_ns_floor64(k_uptime_ticks());
	struct datapoint kin_dp = {
		.timestamp_ns = ts,
		.type = AURORA_DATA_SM_KINEMATICS,
		.channel_count = 2,
	};
	sensor_value_from_double(&kin_dp.channels[0], sm_in.acceleration);
	sensor_value_from_double(&kin_dp.channels[1], sm_in.accel_vert);
	log_enqueue(&kin_dp);

	struct datapoint pose_dp = {
		.timestamp_ns = ts,
		.type = AURORA_DATA_SM_POSE,
		.channel_count = 2,
	};
	sensor_value_from_double(&pose_dp.channels[0], sm_in.velocity);
	sensor_value_from_double(&pose_dp.channels[1], sm_in.altitude);
	log_enqueue(&pose_dp);

	struct datapoint or_dp = {
		.timestamp_ns = ts,
		.type = AURORA_DATA_ORIENTATION,
		.channel_count = 3,
	};
	sensor_value_from_double(&or_dp.channels[0], sm_in.orientation[0]);
	sensor_value_from_double(&or_dp.channels[1], sm_in.orientation[1]);
	sensor_value_from_double(&or_dp.channels[2], sm_in.orientation[2]);
	log_enqueue(&or_dp);
}

#if DT_HAS_CHOSEN(auxspace_vbat)
/* Battery voltage changes slowly; cap the ADC sample rate independently of
 * the (much faster) state-machine telemetry cadence.
 */
#define LOG_VBAT_PERIOD_MS 500

static const struct device *const vbat_dev = DEVICE_DT_GET(DT_CHOSEN(auxspace_vbat));

void log_vbat_telemetry(void)
{
	static int64_t next_sample_ms;

	int64_t now = k_uptime_get();
	if (now < next_sample_ms) {
		return;
	}
	next_sample_ms = now + LOG_VBAT_PERIOD_MS;

	if (!device_is_ready(vbat_dev)) {
		return;
	}

	struct sensor_value voltage;
	if (sensor_sample_fetch(vbat_dev) != 0 ||
	    sensor_channel_get(vbat_dev, SENSOR_CHAN_VOLTAGE, &voltage) != 0) {
		LOG_WRN("vbat read failed");
		return;
	}

	struct datapoint dp = {
		.timestamp_ns = k_ticks_to_ns_floor64(k_uptime_ticks()),
		.type = AURORA_DATA_VBAT,
		.channel_count = 1,
		.channels = {voltage},
	};
	log_enqueue(&dp);
}
#else
/* No battery-sense node in the devicetree — nothing to log. */
void log_vbat_telemetry(void) {}
#endif /* DT_HAS_CHOSEN(auxspace_vbat) */
#endif

#if defined(CONFIG_AURORA_PAD_LINK)

void update_pad_link_data(void)
{
	struct sm_inputs sm_snap;

	sm_get_inputs(&sm_snap);
	pad_link_publish_sm(sm_get_state(), sm_get_type(), &sm_snap);
}
#endif /* CONFIG_AURORA_PAD_LINK */
```

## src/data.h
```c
/**
 * @file data.h
 * @brief Flight-time logging glue for the flight computer state machine.
 *
 * Copyright (c) 2025-2026 Auxspace e.V.
 * SPDX-License-Identifier: Apache-2.0
 */

#ifndef DATA_H
#define DATA_H

#include <stdbool.h>

#include <aurora/lib/baro.h>
#include <aurora/lib/state/state.h>

#if defined(CONFIG_DATA_LOGGER_BIN)
void log_handle_flight_lifecycle(const enum sm_state prev_state, const enum sm_state state);
void log_flight_telemetry(void);
void log_vbat_telemetry(void);
#else
static inline void log_handle_flight_lifecycle(const enum sm_state prev_state, const enum sm_state state) {}
static inline void log_flight_telemetry(void) {}
static inline void log_vbat_telemetry(void) {}
#endif /* CONFIG_DATA_LOGGER_BIN */

#if defined(CONFIG_AURORA_PAD_LINK)
void update_pad_link_data(void);
#else
static inline void update_pad_link_data(void) {}
#endif /*CONFIG_AURORA_PAD_LINK*/

/**
 * @brief Arming precondition: is flight-time data logging available?
 *
 * Feeds @ref sm_inputs.log_ready so the state machine refuses to leave IDLE
 * for ARMED and drops back from ARMED to IDLE pre-boost when the flight
 * cannot be recorded.  False when the boot-time disk bring-up found the raw
 * flight-log region unusable (with CONFIG_DATA_LOGGER_DISK_AUTO_MKFS), or
 * once opening the flight log at ARM time has failed (latched until
 * reboot).  Builds without the binary logger have nothing to gate on and
 * always report ready.
 */
#if defined(CONFIG_DATA_LOGGER_BIN)
bool log_flight_log_online(void);
#else
static inline bool log_flight_log_online(void) { return true; }
#endif /* CONFIG_DATA_LOGGER_BIN */

#endif /* DATA_H */
```

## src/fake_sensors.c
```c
/**
 * @file fake_sensors.c
 * @brief Synthetic IMU and baro data source for sim-based testing.
 *
 * When CONFIG_AURORA_FAKE_SENSORS is enabled, replaces the real polling
 * threads in main.c with a canned flight profile generator. Publishes on
 * the same zbus channels (imu_data_chan, baro_data_chan) at the same
 * cadence and priorities, so downstream code (attitude, Kalman filter,
 * state machine, data logger) runs unchanged. Works on native_sim and on
 * real hardware targets; layer via the `sim` snippet (-S sim).
 *
 * The profile is kicked off by the shell command `sim launch` and can
 * be returned to pad-stationary with `sim reset`. Altitude and pressure
 * follow ISA troposphere; accelerometer reports proper acceleration
 * (includes +g on Z when stationary or under parachute, ~0 in free-fall).
 *
 * Copyright (c) 2025-2026 Auxspace e.V.
 * SPDX-License-Identifier: Apache-2.0
 */

#include "aurora/lib/state/state.h"
#include <math.h>
#include <stdint.h>
#include <stdlib.h>
#include <zephyr/kernel.h>
#include <zephyr/logging/log.h>
#include <zephyr/shell/shell.h>
#include <zephyr/zbus/zbus.h>
#include <zephyr/logging/log_ctrl.h>

#include <aurora/lib/imu.h>
#include <aurora/lib/baro.h>

#ifndef M_PI
#define M_PI ((double)3.14159265358979323846)
#endif

LOG_MODULE_REGISTER(fake_sensors, CONFIG_FLIGHT_COMPUTER_LOG_LEVEL);

/* baro_active / imu_active are owned by main.c; the state machine waits on
 * them before entering its loop.
 */
extern bool baro_active;
extern bool imu_active;

/* -------- Flight profile constants -------- */

#define GRAVITY_MS2              9.81
/* Coordinate (not proper) acceleration produced by the motor during boost. */
#define BOOST_COORD_ACCEL_MS2    30.0
#define BOOST_DURATION_S         1.5
/* Roll rate (rotation about the rocket's long axis) injected into the
 * gyro after launch.  Must be non-zero so the autotest can verify roll
 * is being integrated.  Held at zero pre-launch so attitude calibration
 * sees a stationary IMU and captures a zero gyro bias.
 */
#define ROLL_RATE_DPS            30.0
/* Parachute descent rate applied after apogee. */
#define DROGUE_RATE_MS           12.0
#define MAIN_RATE_MS             4.0

/* ISA troposphere, matching the constants in lib/sensor/baro.c */
#define SEA_LEVEL_PRESSURE_KPA   101.325
#define ISA_T0                   288.15
#define ISA_L                    0.0065
#define ISA_GMR_OVER_L           5.25588

/* -------- Calibration signal (written by main.c, read by autolaunch) -------- */

static struct k_spinlock cal_lock;
static bool calibration_done;

/**
 * @brief Notify the automatic launch sequence that attitude calibration is complete.
 */
void fake_sensors_on_calibrated(void)
{
	k_spinlock_key_t key = k_spin_lock(&cal_lock);
	calibration_done = true;
	k_spin_unlock(&cal_lock, key);
}

/* -------- Launch trigger state (shared with shell command) -------- */

static struct k_spinlock profile_lock;
/** Uptime (ms) at which `sim launch` fired. 0 means not yet launched. */
static uint64_t launch_uptime_ns;

static uint64_t profile_launch_get(void)
{
	k_spinlock_key_t key = k_spin_lock(&profile_lock);
	uint64_t v = launch_uptime_ns;
	k_spin_unlock(&profile_lock, key);
	return v;
}

static void profile_launch_set(uint64_t v)
{
	k_spinlock_key_t key = k_spin_lock(&profile_lock);
	launch_uptime_ns = v;
	k_spin_unlock(&profile_lock, key);
}

/* -------- Profile math -------- */

/**
 * @brief Compute altitude (AGL) and proper Z-axis acceleration at flight time.
 *
 * @param t_s Seconds since launch; negative means stationary on the pad.
 */
static void profile_sample(double t_s, double *altitude_m, double *accel_vert_ms2)
{
	static double t_to_main = 0.0;

	if (t_s < 0.0) {
		*altitude_m = 0.0;
		*accel_vert_ms2 = GRAVITY_MS2;
		return;
	}

	if (t_s < BOOST_DURATION_S) {
		*altitude_m = 0.5 * BOOST_COORD_ACCEL_MS2 * t_s * t_s;
		*accel_vert_ms2 = BOOST_COORD_ACCEL_MS2 + GRAVITY_MS2;
		return;
	}

	const double v_burnout = BOOST_COORD_ACCEL_MS2 * BOOST_DURATION_S;
	const double h_burnout = 0.5 * BOOST_COORD_ACCEL_MS2 *
				 BOOST_DURATION_S * BOOST_DURATION_S;
	const double t_coast = t_s - BOOST_DURATION_S;
	const double v = v_burnout - GRAVITY_MS2 * t_coast;
	const enum sm_state state = sm_get_state();

	if (state < SM_APOGEE) {
		if (v < 0.0) {
			LOG_WRN_ONCE("Simulator APOGEE; State machine %s", sm_state_str(state));
		}
		*altitude_m = h_burnout + v_burnout * t_coast -
			      0.5 * GRAVITY_MS2 * t_coast * t_coast;
		*accel_vert_ms2 = 0.0; /* ballistic coast: accelerometer reads 0 */
		return;
	} else if (state == SM_MAIN && t_to_main == 0.0) {
		t_to_main = t_s;
	}

	/* After apogee: approximate instant parachute, constant descent rate. */
	const double t_to_apogee = v_burnout / GRAVITY_MS2;
	const double h_apogee = h_burnout + v_burnout * t_to_apogee -
				0.5 * GRAVITY_MS2 * t_to_apogee * t_to_apogee;
	const double t_after_apogee = t_coast - t_to_apogee;
	const double t_main = t_to_main == 0.0 ? 0.0 : t_s - t_to_main;
	const double t_apogee_to_main = t_after_apogee - t_main;

	double h = h_apogee - DROGUE_RATE_MS * t_apogee_to_main -
		   MAIN_RATE_MS * t_main;
	if (h < 0.0) {
		h = 0.0;
	}
	*altitude_m = h;
	*accel_vert_ms2 = GRAVITY_MS2; /* terminal descent or landed */
}

static double altitude_to_pressure_kpa(double h_m)
{
	const double ratio = 1.0 - ISA_L * h_m / ISA_T0;
	if (ratio <= 0.0) {
		return 0.01;
	}
	return SEA_LEVEL_PRESSURE_KPA * pow(ratio, ISA_GMR_OVER_L);
}

static void set_sensor_value_double(struct sensor_value *sv, double v)
{
	sv->val1 = (int32_t)v;
	sv->val2 = (int32_t)((v - (double)sv->val1) * 1000000.0);
}

static double flight_time_seconds(void)
{
	uint64_t launch = profile_launch_get();
	if (launch == 0) {
		return -1.0;
	}
	return (double)(k_ticks_to_ns_floor64(k_uptime_ticks()) - launch) / 1000000000.0;
}

/* -------- Synthetic IMU thread -------- */

static void fake_imu_task(void *, void *, void *)
{
	const int hz = CONFIG_IMU_FREQUENCY;
	const uint64_t period_ns = 1000000000 / hz;

	LOG_INF("Fake IMU running at %d Hz", hz);
	imu_active = true;

	while (1) {
		uint64_t start = k_ticks_to_ns_floor64(k_uptime_ticks());
		double altitude, accel_vert;
		profile_sample(flight_time_seconds(), &altitude, &accel_vert);

		/* Inject a constant roll rate about the configured up axis once
		 * the flight is in progress (t_s >= 0).  Pre-launch the gyro
		 * stays at zero so the attitude calibration window captures a
		 * zero bias.
		 */
		const double t_s = flight_time_seconds();
		double gyro_axes[3] = {0.0, 0.0, 0.0};
		if (t_s >= 0.0) {
			gyro_axes[CONFIG_IMU_UP_AXIS_INDEX] =
				ROLL_RATE_DPS * (M_PI / 180.0) *
				(double)CONFIG_IMU_UP_AXIS_SIGN;
		}

		struct imu_data msg = {0};
		set_sensor_value_double(&msg.accel[0], 0.0);
		set_sensor_value_double(&msg.accel[1], accel_vert);
		set_sensor_value_double(&msg.accel[2], 0.0);
		set_sensor_value_double(&msg.gyro[0], gyro_axes[0]);
		set_sensor_value_double(&msg.gyro[1], gyro_axes[1]);
		set_sensor_value_double(&msg.gyro[2], gyro_axes[2]);

		(void)zbus_chan_pub(&imu_data_chan, &msg, K_NO_WAIT);
		uint64_t delta = k_ticks_to_ns_floor64(k_uptime_ticks()) - start;

		k_sleep(K_NSEC(period_ns - delta));
	}
}

K_THREAD_DEFINE(imu_polling, 2048, fake_imu_task, NULL, NULL, NULL,
		5, 0, 0);

/* -------- Synthetic baro thread -------- */

static void fake_baro_task(void *, void *, void *)
{
	const int hz = CONFIG_BARO_FREQUENCY;
	const uint64_t period_ns = 1000000000 / hz;

	LOG_INF("Fake baro running at %d Hz", hz);
	baro_active = true;

	while (1) {
		uint64_t start = k_ticks_to_ns_floor64(k_uptime_ticks());
		double altitude, accel_vert;
		profile_sample(flight_time_seconds(), &altitude, &accel_vert);

		struct baro_data msg = {0};
		set_sensor_value_double(&msg.temperature, 20.0);
		set_sensor_value_double(&msg.pressure,
				       altitude_to_pressure_kpa(altitude));

		(void)zbus_chan_pub(&baro_data_chan, &msg, K_NO_WAIT);

		uint64_t delta = k_ticks_to_ns_floor64(k_uptime_ticks()) - start;

		k_sleep(K_NSEC(period_ns - delta));
	}
}

K_THREAD_DEFINE(baro_polling, 2048, fake_baro_task, NULL, NULL, NULL,
		5, 0, 0);

/* -------- Shell interface -------- */

static int cmd_sim_launch(const struct shell *sh, size_t argc, char **argv)
{
	ARG_UNUSED(argc);
	ARG_UNUSED(argv);

	profile_launch_set(k_ticks_to_ns_floor64(k_uptime_ticks()));
	shell_print(sh, "sim: flight profile launched");
	return 0;
}

static int cmd_sim_reset(const struct shell *sh, size_t argc, char **argv)
{
	ARG_UNUSED(argc);
	ARG_UNUSED(argv);

	profile_launch_set(0);
	shell_print(sh, "sim: flight profile reset (pad-stationary)");
	return 0;
}

static int cmd_sim_status(const struct shell *sh, size_t argc, char **argv)
{
	ARG_UNUSED(argc);
	ARG_UNUSED(argv);

	double t = flight_time_seconds();
	double altitude, accel_vert;
	profile_sample(t, &altitude, &accel_vert);

	if (t < 0.0) {
		shell_print(sh, "sim: pad-stationary");
	} else {
		shell_print(sh, "sim: t=%.2fs  h=%.2fm  a_vert=%.2fm/s^2",
			    t, altitude, accel_vert);
	}
	return 0;
}

SHELL_STATIC_SUBCMD_SET_CREATE(sim_subcmds,
	SHELL_CMD(launch, NULL,
		  "Start the synthetic flight profile",
		  cmd_sim_launch),
	SHELL_CMD(reset, NULL,
		  "Reset the profile back to pad-stationary",
		  cmd_sim_reset),
	SHELL_CMD(status, NULL,
		  "Print current synthetic-flight state",
		  cmd_sim_status),
	SHELL_SUBCMD_SET_END
);

SHELL_CMD_REGISTER(sim, &sim_subcmds,
		   "Synthetic flight-profile simulator", NULL);

#if defined(CONFIG_AURORA_SIM_AUTOTEST)
/**
 * @brief run an automatic launch sequence and exit when it lands or hits an error.
 */
static void autolaunch_task(void *, void *, void *)
{
	LOG_INF("autolaunch: waiting for attitude calibration...");
	bool done = false;
	while (!done) {
		k_spinlock_key_t key = k_spin_lock(&cal_lock);
		done = calibration_done;
		k_spin_unlock(&cal_lock, key);
		if (done) {
			break;
		}
		k_msleep(50);
	}

	LOG_INF("autolaunch: launching flight profile");
	profile_launch_set(k_ticks_to_ns_floor64(k_uptime_ticks()));

	int64_t deadline = k_uptime_get() + CONFIG_AURORA_SIM_AUTOLAUNCH_TIMEOUT_MS;

	while (1) {
		enum sm_state s = sm_get_state();

		if (s == SM_LANDED) {
			/* Sanity-check that yaw, pitch and roll were tracked
			 * end-to-end.  With the fake profile the rocket stays
			 * vertical (yaw ~ 0, pitch ~ 0) and spins about the up
			 * axis at ROLL_RATE_DPS, so roll must have moved away
			 * from zero by the time we land.
			 */
			struct sm_inputs sm_in;
			sm_get_inputs(&sm_in);
			LOG_INF("autolaunch: orientation yaw=%.2f pitch=%.2f roll=%.2f",
				sm_in.orientation[0], sm_in.orientation[1],
				sm_in.orientation[2]);
			__ASSERT(fabs(sm_in.orientation[0]) < 5.0,
				 "autolaunch: yaw drift %.2f deg exceeds 5 deg",
				 sm_in.orientation[0]);
			__ASSERT(fabs(sm_in.orientation[1]) < 5.0,
				 "autolaunch: pitch drift %.2f deg exceeds 5 deg",
				 sm_in.orientation[1]);
			__ASSERT(fabs(sm_in.orientation[2]) > 1.0,
				 "autolaunch: roll did not integrate (%.2f deg)",
				 sm_in.orientation[2]);

			LOG_INF("autolaunch: LANDED - simulation complete");
			log_flush();
			exit(0);
		}
		if (s == SM_ERROR) {
			/* __ASSERT_NO_MSG in error handler likely fires first */
			LOG_ERR("autolaunch: ERROR state - simulation failed");
			log_flush();
			exit(1);
		}
		if (k_uptime_get() >= deadline) {
			LOG_ERR("autolaunch: ERROR - timeout after %d ms without landing",
				CONFIG_AURORA_SIM_AUTOLAUNCH_TIMEOUT_MS);
			log_flush();
			exit(1);
		}
		k_msleep(100);
	}
}

K_THREAD_DEFINE(autolaunch, 1024, autolaunch_task, NULL, NULL, NULL, 5, 0, 0);

#endif /* CONFIG_AURORA_SIM_AUTOTEST */
```

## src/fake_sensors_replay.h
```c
/*
 * Copyright (c) 2025-2026 Auxspace e.V.
 * SPDX-License-Identifier: Apache-2.0
 */

#ifndef FAKE_SENSORS_REPLAY_H_
#define FAKE_SENSORS_REPLAY_H_

#include <stddef.h>
#include <stdint.h>

struct replay_imu_sample {
	uint64_t t_ns;
	float x, y, z;
};

struct replay_baro_sample {
	uint64_t t_ns;
	float pres_kpa, temp_c;
};

extern const struct replay_imu_sample replay_accel[];
extern const size_t replay_accel_len;
extern const struct replay_imu_sample replay_gyro[];
extern const size_t replay_gyro_len;
extern const struct replay_baro_sample replay_baro[];
extern const size_t replay_baro_len;

#endif /* FAKE_SENSORS_REPLAY_H_ */
```
